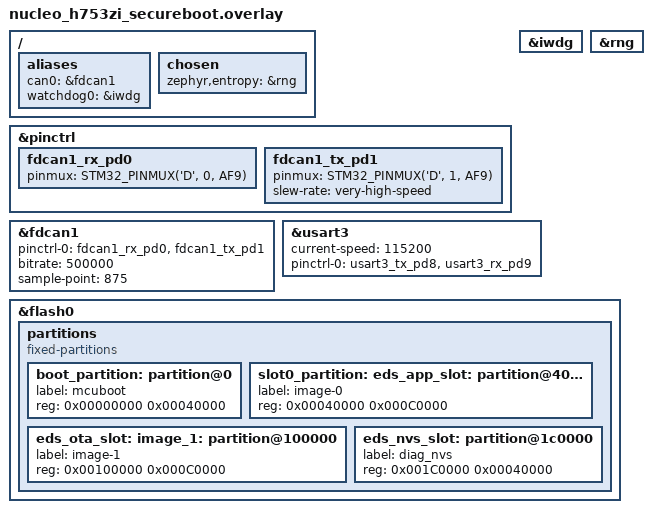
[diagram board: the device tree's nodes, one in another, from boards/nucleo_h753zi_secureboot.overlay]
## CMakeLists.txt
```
# =============================================================================
# Xaloqi Zephyr-Reference-ECU
# CMakeLists.txt (project root)
#
# PURPOSE: Wires Xaloqi EDS — pulled in as a west module (see west.yml) — plus
#          this repo's own application sources into a single Zephyr app
#          target, with optional code generation from diagnostics_config.yaml.
#
#          Phase 1 (this phase): native_sim only. The real-hardware board
#          target lands in Phase 2 — see README.md.
#
# USAGE:
#   west build -b native_sim .
#
#   # Skip codegen if generated/ files are already present (the default for
#   # a fresh clone — see "Pre-committed generated C" in README.md):
#   west build -b native_sim . -- -DDIAG_SKIP_CODEGEN=ON
#
# SPDX-License-Identifier: Apache-2.0
# =============================================================================

cmake_minimum_required(VERSION 3.20.0)

# ---------------------------------------------------------------------------
# Option: CAN FD (the Pi 5 CAN FD bench), CAN build only
#
#   nucleo_h753zi: FDCAN1 in CAN FD mode with a 2 Mbit/s data phase
#                  (boards/nucleo_h753zi_canfd.*; arbitration unchanged at 500 kbit/s)
#   xenvm:         CAN FD over virtio-can (boards/xenvm_can_fd.conf; xenvm/run.sh can
#                  with XENVM_CAN_FD=1)
# and, on both, EDS's ISO-TP built with CAN FD (ISOTP_ENABLE_CAN_FD, use_fd set
# in src/main.c). Off by default, so the default images are unchanged. Must come
# before find_package(Zephyr), which reads the extra conf and overlay.
# ---------------------------------------------------------------------------
option(DIAG_CAN_FD "CAN FD on the CAN controller and in ISO-TP (nucleo_h753zi, xenvm)" OFF)
if(DIAG_CAN_FD)
    if(DIAG_DOIP_ONLY_BUILD)
        message(FATAL_ERROR "[REF-ECU] DIAG_CAN_FD is a CAN option; it cannot combine with DIAG_DOIP_ONLY_BUILD.")
    endif()
    if(BOARD MATCHES "^nucleo_h753zi")
        list(APPEND EXTRA_CONF_FILE ${CMAKE_CURRENT_SOURCE_DIR}/boards/nucleo_h753zi_canfd.conf)
        list(APPEND EXTRA_DTC_OVERLAY_FILE ${CMAKE_CURRENT_SOURCE_DIR}/boards/nucleo_h753zi_canfd.overlay)
    elseif(BOARD MATCHES "^xenvm")
        list(APPEND EXTRA_CONF_FILE ${CMAKE_CURRENT_SOURCE_DIR}/boards/xenvm_can_fd.conf)
    else()
        message(FATAL_ERROR "[REF-ECU] DIAG_CAN_FD is defined for nucleo_h753zi and xenvm only (got '${BOARD}').")
    endif()
endif()

find_package(Zephyr REQUIRED HINTS $ENV{ZEPHYR_BASE})

project(zephyr_reference_ecu
    VERSION     0.1.0
    LANGUAGES   C
    DESCRIPTION "Xaloqi Zephyr-Reference-ECU — ReferenceBCM"
)

set(CMAKE_C_STANDARD          11)
set(CMAKE_C_STANDARD_REQUIRED ON)
set(CMAKE_C_EXTENSIONS        OFF)

# ---------------------------------------------------------------------------
# Compiler flags
#
# -Wpedantic and -Wconversion are deliberately absent — Zephyr's own headers
# trip both (C11/GCC extensions, cbprintf sign-conversion noise). Same
# exclusion EDS's own examples make, for the same reason.
# ---------------------------------------------------------------------------
target_compile_options(app PRIVATE
    -Wall
    -Wextra
    -Wshadow
    -Wdouble-promotion
    -Wundef
    -Wno-unused-parameter
    -Wno-sign-conversion
)

# ---------------------------------------------------------------------------
# Xaloqi EDS — resolved via the west module variable Zephyr's module system
# generates from EDS's zephyr/module.yml ("name: xaloqi-eds").
# ---------------------------------------------------------------------------
if(NOT DEFINED ZEPHYR_XALOQI_EDS_MODULE_DIR)
    message(FATAL_ERROR
        "\n"
        "[REF-ECU] ERROR: Xaloqi EDS west module not found.\n"
        "       Expected ZEPHYR_XALOQI_EDS_MODULE_DIR to be set by Zephyr's\n"
        "       module system (see west.yml and EDS's zephyr/module.yml).\n"
        "       Did you run 'west update'?\n"
    )
endif()

set(DIAG_ROOT "${ZEPHYR_XALOQI_EDS_MODULE_DIR}")

set(DIAG_CONFIG_YAML    "${CMAKE_CURRENT_SOURCE_DIR}/diagnostics_config.yaml")
set(DIAG_CODEGEN_SCRIPT "${DIAG_ROOT}/tools/codegen.py")
set(DIAG_GENERATED_DIR  "${CMAKE_CURRENT_SOURCE_DIR}/generated")

# Sentinel: file whose timestamp CMake uses to detect when codegen must re-run.
set(CODEGEN_SENTINEL "${DIAG_GENERATED_DIR}/safety_config.h")

# ---------------------------------------------------------------------------
# Option: disable automatic code generation
#
# Default OFF matches EDS's own examples. A fresh clone of THIS repo should
# flip it ON implicitly via the configure-time check below: codegen needs
# the commercial tools/templates/ this repo does not ship (see
# COMMERCIAL_NOTICE.md) — rather than fail with a confusing Jinja2 error,
# detect the missing templates and fall back to the pre-committed generated/
# tree with a clear message.
# ---------------------------------------------------------------------------
option(DIAG_SKIP_CODEGEN
    "Skip auto-running EDS's tools/codegen.py (use pre-existing generated/ files)"
    OFF
)

# ---------------------------------------------------------------------------
# Option: build the DoIP-only variant (Phase 4) instead of CAN
#
# Selects src/main_doip.c instead of src/main.c, and DoIP transport sources
# instead of ISO-TP/CAN — never both in the same image. See src/main_doip.c's
# own header comment for why this repo does not attempt to run CAN and DoIP
# concurrently (EDS ships no proven architecture for it).
# ---------------------------------------------------------------------------
option(DIAG_DOIP_ONLY_BUILD
    "Build the DoIP transport variant (src/main_doip.c) instead of CAN (src/main.c)"
    OFF
)

# ---------------------------------------------------------------------------
# Option: secure boot (Phase 4) — MCUboot image-policy gate, CAN or DoIP
#
# Adds EDS's flash-ops + MCUboot image-policy sources and the boot-confirm /
# image-policy-registration calls in src/main.c or src/main_doip.c (guarded
# by the DIAG_SECURE_BOOT_BUILD compile definition this sets). Combines with
# DIAG_DOIP_ONLY_BUILD for firmware download over DoIP [EDS#425]. Requires building
# and flashing MCUboot itself separately, and the MCUboot-aware partition
# table in boards/nucleo_h753zi_secureboot.overlay — see README.md "Phase 4".
#
# Scoped to exactly what EDS ships today: MCUboot swap, image-policy gate,
# fail-closed production guard. Firmware authenticity / anti-rollback
# (EDS#319) is open upstream and explicitly excluded.
# ---------------------------------------------------------------------------
option(DIAG_SECURE_BOOT_BUILD
    "Add MCUboot image-policy support (requires MCUboot built and flashed separately)"
    OFF
)

# ---------------------------------------------------------------------------
# Option: bench-only slow RoutineControl (RID 0xF0F0), as in EDS's basic_ecu
#
# A 0x31 routine that answers NRC 0x78 and busy-waits in bounded steps, so the
# response-pending cadence (0x78 keepalives, P2/P2*) can be measured on this
# ECU without flash wear [EDS#282]. Default OFF: a normal image has no 0xF0F0.
# NOT FOR PRODUCTION. Needs an EDS that has the generic response-pending path
# (EDS#555/#559, after v1.26.1); the configure step says so if the pinned EDS
# does not.
# ---------------------------------------------------------------------------
option(DIAG_BENCH_SLOW_ROUTINE
    "Bench only: slow 0x31 routine (RID 0xF0F0) for the response-pending path"
    OFF
)

# DIAG_CAN_FD (declared before find_package above): every EDS source is compiled
# into this app target, so all of them see the same ISOTP_ENABLE_CAN_FD, which
# changes isotp_ctx_t's layout.
if(DIAG_CAN_FD)
    target_compile_definitions(app PRIVATE ISOTP_ENABLE_CAN_FD=1 DIAG_CAN_FD=1)
endif()

# ---------------------------------------------------------------------------
# DIAG_CAN_ECU_INDEX — ISO 15765-4 physical address pair of this ECU (CAN build).
# Unset (the default): the generated response ID (0x7E8) and physical request ID
# 0x7E0, so every existing image is unchanged. 0..7: request 0x7E0+n, response
# 0x7E8+n, so two of these ECUs can share one bus (the Pi 5 bench runs the
# NUCLEO as ECU 0 and the xenvm DomZ as ECU 1). The functional ID 0x7DF stays
# shared, as ISO 15765-4 intends: each ECU answers it on its own response ID.
# ---------------------------------------------------------------------------
set(DIAG_CAN_ECU_INDEX "" CACHE STRING "ISO 15765-4 ECU index 0..7 (empty: generated IDs)")
if(NOT DIAG_CAN_ECU_INDEX STREQUAL "")
    if(NOT DIAG_CAN_ECU_INDEX MATCHES "^[0-7]$")
        message(FATAL_ERROR "DIAG_CAN_ECU_INDEX must be 0..7, got '${DIAG_CAN_ECU_INDEX}'")
    endif()
    target_compile_definitions(app PRIVATE DIAG_CAN_ECU_INDEX=${DIAG_CAN_ECU_INDEX}U)
endif()

if(NOT DIAG_SKIP_CODEGEN AND NOT EXISTS "${DIAG_ROOT}/tools/templates")
    message(STATUS
        "[REF-ECU] Commercial tools/templates/ not present (expected — this "
        "is the free tier). Using the pre-committed generated/ tree instead. "
        "See README.md 'Tiers'.")
    set(DIAG_SKIP_CODEGEN ON)
endif()

if(NOT DIAG_SKIP_CODEGEN)

    find_package(Python3 COMPONENTS Interpreter QUIET)

    if(NOT Python3_FOUND)
        message(FATAL_ERROR
            "\n"
            "[REF-ECU] ERROR: Python3 interpreter not found.\n"
            "       Cannot run EDS's tools/codegen.py.\n"
            "       Install Python3 (>= 3.9) with: pip install pyyaml jinja2\n"
            "       Or build with -DDIAG_SKIP_CODEGEN=ON to use the\n"
            "       pre-committed generated/ tree instead.\n"
        )
    endif()

    file(GLOB DIAG_TEMPLATES "${DIAG_ROOT}/tools/templates/*.j2")

    add_custom_command(
        OUTPUT   "${CODEGEN_SENTINEL}"
        COMMAND  "${Python3_EXECUTABLE}"
                 "${DIAG_CODEGEN_SCRIPT}"
                 --config "${DIAG_CONFIG_YAML}"
                 --out    "${DIAG_GENERATED_DIR}"
                 --safety-wrappers
                 --asil-level B
                 --no-manifest
        DEPENDS
            "${DIAG_CONFIG_YAML}"
            "${DIAG_CODEGEN_SCRIPT}"
            ${DIAG_TEMPLATES}
        COMMENT  "[REF-ECU] Generating sources from diagnostics_config.yaml (ASIL-B)..."
        VERBATIM
    )

    add_custom_target(run_codegen
        DEPENDS "${CODEGEN_SENTINEL}"
        COMMENT "[REF-ECU] run_codegen complete."
    )

else()

    message(STATUS
        "[REF-ECU] DIAG_SKIP_CODEGEN=ON — using existing files in ${DIAG_GENERATED_DIR}")

endif()

# ---------------------------------------------------------------------------
# Configure-time check: the one hand-edited "generated/ delta" this repo
# makes (generated/routine_handlers.c's four [APP HOOK] bodies — see that
# file's own banner and src/bcm_state.h) must survive a regeneration.
# ---------------------------------------------------------------------------
if(EXISTS "${DIAG_GENERATED_DIR}/routine_handlers.c")
    file(READ "${DIAG_GENERATED_DIR}/routine_handlers.c" _ROUTINE_HANDLERS_SRC)
    string(FIND "${_ROUTINE_HANDLERS_SRC}" "[APP HOOK]" _APP_HOOK_POS)
    if(_APP_HOOK_POS EQUAL -1)
        message(FATAL_ERROR
            "\n"
            "[REF-ECU] ERROR: generated/routine_handlers.c no longer contains "
            "the [APP HOOK] markers.\n"
            "       If you regenerated this file from diagnostics_config.yaml, "
            "reapply the four bodies documented in src/bcm_state.h, or this "
            "ECU's RoutineControl actuations silently do nothing.\n"
        )
    endif()
endif()

# ---------------------------------------------------------------------------
# Include directories
# ---------------------------------------------------------------------------
target_include_directories(app PRIVATE
    ${DIAG_ROOT}/core
    ${DIAG_ROOT}/core/uds_services
    ${DIAG_ROOT}/transport
    ${DIAG_ROOT}/config
    ${DIAG_ROOT}/platform
    ${DIAG_ROOT}/platform/zephyr
    ${DIAG_GENERATED_DIR}
    ${CMAKE_CURRENT_SOURCE_DIR}/src
)
if(DIAG_DOIP_ONLY_BUILD)
    target_include_directories(app PRIVATE ${DIAG_ROOT}/transport/doip)
endif()

# ---------------------------------------------------------------------------
# Source files
# ---------------------------------------------------------------------------
include(${DIAG_ROOT}/cmake/eds_service_sources.cmake)

target_sources(app PRIVATE

    # ── This repo's own application layer (Apache-2.0) ────────────────────
    ${CMAKE_CURRENT_SOURCE_DIR}/src/bcm_state.c
    ${CMAKE_CURRENT_SOURCE_DIR}/src/bcm_storage.c
    ${CMAKE_CURRENT_SOURCE_DIR}/src/bcm_debounce.c

    # ── EDS UDS core ────────────────────────────────────────────────────
    ${DIAG_ROOT}/core/uds_server.c
    ${DIAG_ROOT}/core/uds_session.c
    ${DIAG_ROOT}/core/uds_security.c
    ${DIAG_ROOT}/core/uds_safety.c
    ${DIAG_ROOT}/core/uds_security_algo.c
    ${DIAG_ROOT}/core/uds_aes_cmac.c
    ${DIAG_ROOT}/core/uds_access_table.c
    ${DIAG_ROOT}/core/uds_comm_control.c
    ${DIAG_ROOT}/core/uds_session_stats.c
    ${DIAG_ROOT}/core/uds_security_nvm.c
    ${EDS_SERVICE_SRCS}
    ${DIAG_ROOT}/core/uds_transfer_ctx.c
    ${DIAG_ROOT}/platform/uds_flash_ops.c
    ${DIAG_ROOT}/platform/uds_image_policy.c

    # ── EDS configuration databases ─────────────────────────────────────
    ${DIAG_ROOT}/config/did_database.c
    ${DIAG_ROOT}/config/dtc_database.c
    ${DIAG_ROOT}/config/routine_database.c
    ${DIAG_ROOT}/config/dtc_mirror.c

    # ── EDS Zephyr platform abstraction (transport-independent) ──────────
    ${DIAG_ROOT}/platform/zephyr/zephyr_mutex.c
    ${DIAG_ROOT}/platform/zephyr/zephyr_platform_api.c
    # Both entry points arm and feed the watchdog (diag_wdt_init/feed);
    # on native_sim (CONFIG_WATCHDOG=n) it compiles to its degraded no-op.
    ${DIAG_ROOT}/platform/zephyr/zephyr_wdt.c

    # ── Generated sources ────────────────────────────────────────────────
    ${DIAG_GENERATED_DIR}/did_handlers.c
    ${DIAG_GENERATED_DIR}/uds_init.c
    ${DIAG_GENERATED_DIR}/did_safety_wrappers.c
    ${DIAG_GENERATED_DIR}/routine_handlers.c
)

# ---------------------------------------------------------------------------
# Transport-specific entry point and sources — CAN (default) or DoIP
# (DIAG_DOIP_ONLY_BUILD), never both. See src/main_doip.c's header comment
# for why this repo does not attempt both transports in one image.
# ---------------------------------------------------------------------------
if(DIAG_DOIP_ONLY_BUILD)
    target_sources(app PRIVATE
        ${CMAKE_CURRENT_SOURCE_DIR}/src/main_doip.c
        ${DIAG_ROOT}/transport/doip/doip_server.c
        ${DIAG_ROOT}/transport/doip/zephyr_lwip.c
        ${DIAG_ROOT}/platform/zephyr/platform_doip.c
    )
    target_compile_definitions(app PRIVATE EDS_DOIP_ONLY_BUILD=1)
else()
    target_sources(app PRIVATE
        ${CMAKE_CURRENT_SOURCE_DIR}/src/main.c
        ${DIAG_ROOT}/transport/isotp.c
        ${DIAG_ROOT}/transport/can_transport.c
        ${DIAG_ROOT}/platform/zephyr/zephyr_can.c
        ${DIAG_ROOT}/platform/zephyr/zephyr_port.c
        ${DIAG_ROOT}/platform/zephyr/zephyr_timer.c
    )
endif()

# ---------------------------------------------------------------------------
# Secure boot — either transport [EDS#425]. Same sources and definition for
# CAN and DoIP; placed after the transport sources so the CAN build's link
# order is unchanged.
# ---------------------------------------------------------------------------
if(DIAG_SECURE_BOOT_BUILD)
    target_sources(app PRIVATE
        # Registered with zephyr_flash_ops_init() by both entry points
        # (src/main.c since #19, src/main_doip.c).
        ${DIAG_ROOT}/platform/zephyr/zephyr_flash_ops.c
        # Called from both entry points (zephyr_mcuboot_image_policy_init())
        ${DIAG_ROOT}/platform/zephyr/zephyr_mcuboot_image_policy.c
        # Streaming SHA-256 + MCUboot header/TLV parser — used by the
        # image-policy digest check above
        ${DIAG_ROOT}/platform/uds_sha256.c
        ${DIAG_ROOT}/platform/uds_mcuboot_image.c
    )
    target_compile_definitions(app PRIVATE DIAG_SECURE_BOOT_BUILD=1)
endif()

# ---------------------------------------------------------------------------
# Bench-only slow routine (DIAG_BENCH_SLOW_ROUTINE), both transports.
# ---------------------------------------------------------------------------
if(DIAG_BENCH_SLOW_ROUTINE)
    if(NOT EXISTS "${DIAG_ROOT}/platform/zephyr/bench_slow_routine.c")
        message(FATAL_ERROR
            "\n"
            "[REF-ECU] ERROR: DIAG_BENCH_SLOW_ROUTINE=ON, but the EDS in "
            "${DIAG_ROOT} has no platform/zephyr/bench_slow_routine.c.\n"
            "       The bench routine ships with EDS#559, after v1.26.1. Point "
            "west.yml's EDS revision at a commit that has it (a local, "
            "uncommitted change is fine for a bench).\n"
        )
    endif()
    target_sources(app PRIVATE ${DIAG_ROOT}/platform/zephyr/bench_slow_routine.c)
    target_compile_definitions(app PRIVATE DIAG_BENCH_SLOW_ROUTINE=1)
endif()

# ---------------------------------------------------------------------------
# NVM store: platform-conditional source selection (same pattern as EDS's
# own examples/safeboot_ecu/CMakeLists.txt, the reference for this exact
# board).
#
#   native_sim      — nvm_store_mock.c, RAM-backed, no real flash to resolve.
#   nucleo_h753zi   — nvm_store_append.c, the append-only backend EDS#304
#                     introduced for STM32H7 boards: their uniform 128 KB
#                     erase sectors exceed nvs_fs.sector_size's uint16_t
#                     range, so nvm_store.c's classic NVS backend cannot
#                     mount this partition at all on this part.
#
# Exactly one must be compiled per build; any two would produce duplicate-
# symbol linker errors (all three define the same nvm_store_* API).
# ---------------------------------------------------------------------------
if(CONFIG_BOARD_NATIVE_SIM)
    target_sources(app PRIVATE ${DIAG_ROOT}/platform/zephyr/nvm_store_mock.c)
elseif(CONFIG_BOARD_NUCLEO_H753ZI)
    target_sources(app PRIVATE ${DIAG_ROOT}/platform/zephyr/nvm_store_append.c)
    target_compile_definitions(app PRIVATE DIAG_NVM_BACKEND_APPEND=1)
else()
    target_sources(app PRIVATE ${DIAG_ROOT}/platform/zephyr/nvm_store.c)
endif()

if(NOT DIAG_SKIP_CODEGEN AND TARGET run_codegen)
    add_dependencies(app run_codegen)
endif()

# Required for the build to compile: _Static_assert in uds_types.h fires at
# translation-unit level whenever sizeof(uds_msg_buf_t) > EDS_MSG_BUF_MAX_STACK_BYTES.
target_compile_definitions(app PRIVATE EDS_MSG_BUF_MAX_STACK_BYTES=8192)
```

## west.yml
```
manifest:
  version: "0.13"

  remotes:
    - name: zephyrproject-rtos
      url-base: https://github.com/zephyrproject-rtos
    - name: xaloqi
      url-base: https://github.com/Xaloqi

  projects:
    - name: zephyr
      remote: zephyrproject-rtos
      revision: v3.7.0
      path: zephyr
      import:
        file: west.yml

    - name: EDS
      remote: xaloqi
      revision: v1.29.0
      path: modules/xaloqi-eds

  self:
    path: Zephyr-Reference-ECU
```

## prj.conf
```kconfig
# =============================================================================
# Xaloqi Zephyr-Reference-ECU
# prj.conf
#
# Base project configuration. native_sim-specific overrides live in
# boards/native_sim.conf (Phase 1 ships no other board target).
# =============================================================================

# --- CAN driver ---
CONFIG_CAN=y
CONFIG_CAN_INIT_PRIORITY=80
CONFIG_STATS=y
CONFIG_CAN_STATS=y

# --- Kernel / threading ---
CONFIG_MULTITHREADING=y
CONFIG_THREAD_STACK_INFO=y
CONFIG_THREAD_NAME=y
CONFIG_THREAD_MONITOR=y

# --- Tick rate: 1 ms required for ISO-TP timer accuracy ---
CONFIG_SYS_CLOCK_TICKS_PER_SEC=1000
CONFIG_TICKLESS_KERNEL=n

# --- Watchdog ---
CONFIG_WATCHDOG=y
CONFIG_WDT_DISABLE_AT_BOOT=n
CONFIG_DIAG_WDT_WINDOW_MS=100

# --- Logging ---
CONFIG_LOG=y
CONFIG_LOG_DEFAULT_LEVEL=3
CONFIG_LOG_BACKEND_UART=y
CONFIG_LOG_BUFFER_SIZE=2048

# --- Safety hardening ---
CONFIG_ASSERT=y
CONFIG_STACK_CANARIES=y
CONFIG_STACK_SENTINEL=y

# --- C library ---
CONFIG_NEWLIB_LIBC=y

# --- No heap (MISRA-21.3) ---
CONFIG_HEAP_MEM_POOL_SIZE=0

# --- UDS stack parameters ---
# S3 and the SecurityAccess lockout come from diagnostics_config.yaml (timing:
# / safety:), not Kconfig. ISO-TP timeouts use EDS's ISO 15765-2:2024 defaults
# (1000 ms). The pins that used to be here were ignored by EDS until
# Xaloqi/EDS#453 and would now force the old 25-150 ms values (Xaloqi/EDS#455).

# --- Diagnostics task ---
CONFIG_DIAG_TASK_STACK_SIZE=4096
CONFIG_DIAG_TASK_PRIORITY=5

# --- Build output ---
CONFIG_BUILD_OUTPUT_BIN=y
CONFIG_BUILD_OUTPUT_HEX=y
```

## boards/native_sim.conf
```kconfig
# =============================================================================
# Xaloqi Zephyr-Reference-ECU
# boards/native_sim.conf
#
# native_sim-specific Kconfig overrides, auto-merged by Zephyr CMake on top
# of prj.conf for this board only (Zephyr convention: <app>/boards/<BOARD>.conf
# is picked up automatically). See Xaloqi EDS's own
# boards/native_sim/native_sim.conf for the full rationale behind each
# override below — Zephyr 3.7 promotes several Kconfig dependency warnings
# to fatal errors on native_sim.
# =============================================================================

CONFIG_CAN_LOOPBACK=y
CONFIG_POSIX_API=y
CONFIG_STACK_CANARIES=n
CONFIG_CAN_STATS=n
CONFIG_LOG_MODE_DEFERRED=y
CONFIG_LOG_BACKEND_UART=n
CONFIG_LOG_BACKEND_NATIVE_POSIX=y
CONFIG_NEWLIB_LIBC=y
CONFIG_REBOOT=y
CONFIG_LOG_DEFAULT_LEVEL=2
CONFIG_WATCHDOG=n
```

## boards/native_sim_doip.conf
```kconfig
# =============================================================================
# Xaloqi Zephyr-Reference-ECU
# boards/native_sim_doip.conf
#
# native_sim loopback-only config for the DoIP build, adapted from Xaloqi
# EDS's own examples/basic_ecu_doip/boards/native_sim/native_sim_doip.conf.
#
# Reachable only from inside the native_sim process itself, not from the
# host OS by any method (CONFIG_NET_LOOPBACK blocks NET_L2_ETHERNET's
# default — a known, disclosed Zephyr/native_sim limitation, EDS#257, not
# something this repo can fix). This file exists for a quick local sanity
# build only, needing no host network setup. For real DoIP bring-up, use
# boards/nucleo_h753zi_doip.conf on real hardware — see README.md "Phase 4".
#
# BUILDING:
#   west build -b native_sim . -- \
#       -DDIAG_SKIP_CODEGEN=ON \
#       -DDIAG_DOIP_ONLY_BUILD=ON \
#       -DEXTRA_CONF_FILE=boards/native_sim_doip.conf
# =============================================================================

CONFIG_POSIX_API=y
CONFIG_NET_LOOPBACK=y
CONFIG_NET_NATIVE=y

# --- Networking base (prj.conf has none — the CAN build needs none) -------
# NET_SOCKETS_POSIX_NAMES intentionally omitted: conflicts with POSIX_API=y.
CONFIG_NETWORKING=y
CONFIG_NET_IPV4=y
CONFIG_NET_TCP=y
CONFIG_NET_SOCKETS=y
CONFIG_NET_IF_MAX_IPV4_COUNT=1
CONFIG_NET_MAX_CONN=8
CONFIG_NET_TCP_MAX_SEND_WINDOW_SIZE=4096
CONFIG_POSIX_MAX_FDS=16

CONFIG_LOG_MODE_DEFERRED=y
CONFIG_LOG_BACKEND_UART=n
CONFIG_LOG_BACKEND_NATIVE_POSIX=y

CONFIG_STACK_CANARIES=n
CONFIG_NEWLIB_LIBC=y

CONFIG_NET_DRIVERS=y
CONFIG_ETH_NATIVE_POSIX=y

CONFIG_LOG_DEFAULT_LEVEL=2
CONFIG_WATCHDOG=n
```

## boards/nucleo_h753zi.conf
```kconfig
# =============================================================================
# Xaloqi Zephyr-Reference-ECU
# boards/nucleo_h753zi.conf
#
# Board-specific Kconfig overrides for the NUCLEO-H753ZI, merged on top of
# prj.conf. Copied from Xaloqi EDS's own confirmed boards/nucleo_h753zi/
# nucleo_h753zi.conf (Zephyr 3.7 / STM32H7 Cortex-M7 specifics — hidden
# Kconfig symbols, MPU vs stack-sentinel conflict, DT-gated CAN/IWDG
# driver selection) — see that file for the full per-symbol rationale.
# =============================================================================

# --- UART3 for ST-LINK virtual COM port logging ------------------------------
CONFIG_SERIAL=y
CONFIG_UART_STM32=y
CONFIG_LOG_BACKEND_UART=y
CONFIG_LOG_MODE_DEFERRED=y
CONFIG_LOG_BUFFER_SIZE=4096

# --- Hardware watchdog (IWDG, DT-gated — do not set CONFIG_WDT_STM32_IWDG) ---
CONFIG_WATCHDOG=y
# Deliberate, not a default: Zephyr's IWDG driver arms the watchdog before
# main() (CONFIG_IWDG_STM32_INITIAL_TIMEOUT, 100 ms), so supervision starts at
# driver init rather than when main() gets round to it -- the earliest any
# option here offers. The cost is a hard budget: everything before
# src/main.c's diag_wdt_init() must finish inside those 100 ms. Measured on
# the bench (CAN build): main() reached at <1 ms uptime -- ~99 ms of margin.
# src/main.c warns at boot if that drops below half the window.
# The DoIP variant cannot meet this budget (its pre-main waits for the network)
# and overrides it -- see boards/nucleo_h753zi_doip.conf.
CONFIG_WDT_DISABLE_AT_BOOT=n

# --- ARM MPU (Cortex-M7, 16-region) ------------------------------------------
CONFIG_ARM_MPU=y
CONFIG_MPU_ALLOW_FLASH_WRITE=y

# --- MPU_STACK_GUARD (auto-selected by ARM_MPU) conflicts with the sentinel --
CONFIG_STACK_SENTINEL=n

# --- Stack canaries: prj.conf's STACK_CANARIES=y stands on this board ---------
# The kernel seeds __stack_chk_guard after PRE_KERNEL_2 through
# entropy_get_entropy_isr() on zephyr,entropy. The STM32 RNG driver initialises
# at PRE_KERNEL_1 and implements that call, so the canary comes from the
# hardware RNG. Canaries do not conflict with the MPU stack guard: the guard
# catches running off the end of a stack, the canary an overrun inside a frame.
# Ask EDS to fail the build if they are ever dropped or not RNG-seeded.
CONFIG_EDS_REQUIRE_STACK_CANARIES=y

# --- Hardware RNG — required for the AES-CMAC SecurityAccess challenge ------
CONFIG_ENTROPY_GENERATOR=y

# --- Flash + NVS (required by platform/nvm_store.c) --------------------------
CONFIG_FLASH=y
CONFIG_FLASH_MAP=y
CONFIG_NVS=y
```

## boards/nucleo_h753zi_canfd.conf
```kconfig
# =============================================================================
# Xaloqi Zephyr-Reference-ECU
# boards/nucleo_h753zi_canfd.conf
#
# Added by -DDIAG_CAN_FD=ON (CMakeLists.txt), on top of nucleo_h753zi.conf:
# FDCAN1 in CAN FD mode for the Pi 5 CAN FD bench. The data-phase timing is in
# boards/nucleo_h753zi_canfd.overlay.
# =============================================================================
CONFIG_CAN_FD_MODE=y
```

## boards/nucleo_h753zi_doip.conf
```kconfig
# =============================================================================
# Xaloqi Zephyr-Reference-ECU
# boards/nucleo_h753zi_doip.conf
#
# Real-hardware DoIP config for the NUCLEO-H753ZI, adapted from Xaloqi EDS's
# own confirmed examples/basic_ecu_doip/boards/nucleo_h753zi/
# nucleo_h753zi_doip.conf — not re-derived.
#
# NUCLEO-H753ZI's Zephyr board support already wires the STM32 Ethernet MAC
# and PHY in devicetree with status "okay" (RMII pinctrl, MDIO) — no board
# overlay needed, only this application-level net stack config.
#
# HOST-SIDE SETUP THIS CONF EXPECTS: a direct Ethernet cable from this board
# to the host machine's own NIC, with the host given a static IP on the same
# /24, e.g.:
#   sudo ip addr add 10.10.10.2/24 dev <host-iface>
# No router, no DHCP server — a direct point-to-point bench link.
#
# JUMPERS: JP6 and JP7 must be ON for Ethernet — see README.md "Phase 4"
# and the bill of materials (PA2/PB13 otherwise conflict with the ST
# Zio/morpho connectors, per Zephyr's own board DTS warning).
#
# BUILDING:
#   west build -b nucleo_h753zi . -- \
#       -DDIAG_SKIP_CODEGEN=ON \
#       -DDIAG_DOIP_ONLY_BUILD=ON \
#       -DEXTRA_CONF_FILE=boards/nucleo_h753zi_doip.conf
# =============================================================================

# --- Networking base (prj.conf has none — the CAN build needs none) -------
CONFIG_NETWORKING=y
CONFIG_NET_IPV4=y
CONFIG_NET_TCP=y
CONFIG_NET_SOCKETS=y
CONFIG_NET_IF_MAX_IPV4_COUNT=1
CONFIG_NET_MAX_CONN=8
CONFIG_NET_TCP_MAX_SEND_WINDOW_SIZE=4096
CONFIG_POSIX_MAX_FDS=16

# --- Real Ethernet driver (auto-selected once NET_L2_ETHERNET is on) -------
CONFIG_NET_L2_ETHERNET=y

# --- Static IPv4 — point-to-point bench link, no DHCP server present -------
CONFIG_NET_CONFIG_SETTINGS=y
CONFIG_NET_CONFIG_NEED_IPV4=y
CONFIG_NET_CONFIG_MY_IPV4_ADDR="10.10.10.1"
CONFIG_NET_CONFIG_MY_IPV4_GW="10.10.10.2"
CONFIG_NET_CONFIG_MY_IPV4_NETMASK="255.255.255.0"

# --- Real hardware: keep console/log on the ST-LINK VCP (board default via
#     zephyr,console = &usart3) ---
CONFIG_LOG=y
CONFIG_LOG_DEFAULT_LEVEL=3

# --- Watchdog: armed by src/main_doip.c, NOT by Zephyr at boot ------------
# Without this line Zephyr's IWDG driver arms the watchdog in
# iwdg_stm32_init(), before main(), with CONFIG_IWDG_STM32_INITIAL_TIMEOUT
# (100 ms). That cannot work on this variant: net_config_init() also runs
# before main() and blocks until the interface is up, bounded only by
# CONFIG_NET_CONFIG_INIT_TIMEOUT (30 s). Measured on the bench, main() starts
# 1.5-4.1 s after boot, depending on the link partner (with the host side
# configured it waits for PHY link-up, ~0.3 s after it), so a boot-armed
# IWDG resets the board every ~100 ms forever (issue #7: RCC_RSR
# 0x04460000 = IWDG1RSTF|PINRSTF|CPURSTF).
#
# So boot-time arming is off, and src/main_doip.c arms the IWDG explicitly
# with diag_wdt_init() at the top of main() and feeds it from the UDS tick
# task. Consequences, stated so nobody infers more:
#   - boot up to main() (1.5-4.1 s measured, up to 30 s) is unsupervised;
#   - from main() on, the UDS tick path and the DoIP server loop are
#     supervised (the loop via EDS#399's check-in); a dead Ethernet link is
#     not -- see "WATCHDOG SUPERVISION" in src/main_doip.c.
# The CAN build deliberately keeps boot-time arming (boards/nucleo_h753zi.conf);
# its pre-main has no network wait. Do not copy this line there.
CONFIG_WDT_DISABLE_AT_BOOT=y
```

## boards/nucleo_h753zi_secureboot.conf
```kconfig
# =============================================================================
# Xaloqi Zephyr-Reference-ECU
# boards/nucleo_h753zi_secureboot.conf
#
# Additive on top of the auto-picked-up boards/nucleo_h753zi.conf (Zephyr
# merges both — this file only needs the MCUboot-specific delta). Adapted
# from Xaloqi EDS's own confirmed examples/safeboot_ecu/boards/nucleo_h753zi/
# nucleo_h753zi.conf.
#
# Full dependency chain (confirmed against the actual subsys/dfu/Kconfig
# source, v3.7.0):
#   menuconfig IMG_MANAGER          depends on STREAM_FLASH
#     choice "Image manager"        default MCUBOOT_IMG_MANAGER
#       MCUBOOT_IMG_MANAGER         depends on FLASH_MAP (already set)
#                                   select MCUBOOT_BOOTUTIL_LIB (provides
#                                   boot_is_img_confirmed()/
#                                   boot_write_img_confirmed())
# CONFIG_STREAM_FLASH is the actual load-bearing one: without it the whole
# IMG_MANAGER menu is invisible, so nothing inside it takes effect no
# matter what else is set here.
# =============================================================================

CONFIG_STREAM_FLASH=y
CONFIG_IMG_MANAGER=y
CONFIG_BOOTLOADER_MCUBOOT=y
CONFIG_MCUBOOT_IMG_MANAGER=y

# --- MCUboot secondary slot write support -----------------------------------
# flash_area_write() requires this to allow writes to non-erase-aligned
# offsets. STM32H753 flash requires 256-bit (32-byte) aligned writes.
CONFIG_FLASH_PAGE_LAYOUT=y
```

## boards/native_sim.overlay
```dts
/ {
	aliases {
		can0 = &can_loopback0;
	};
};

&can_loopback0 {
	status = "okay";
};
```

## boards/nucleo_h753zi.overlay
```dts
/*
 * =============================================================================
 * Xaloqi Zephyr-Reference-ECU
 * boards/nucleo_h753zi.overlay
 *
 * Device Tree overlay for the NUCLEO-H753ZI board — Phase 2 hardware target.
 * FDCAN1 pinmux, bitrate and sample point are reused verbatim from Xaloqi
 * EDS's own confirmed reference (boards/nucleo_h753zi/nucleo_h753zi.overlay
 * in the Xaloqi/EDS repo) — not re-derived here.
 *
 * HARDWARE SETUP (see README.md "Bill of materials"):
 *   NUCLEO-H753ZI → Waveshare SN65HVD230 (3.3V CAN transceiver)
 *   PD0 (FDCAN1_RX) → transceiver RXD
 *   PD1 (FDCAN1_TX) → transceiver TXD
 *   3.3V / GND      → transceiver VCC / GND
 *   CANH / CANL     → the bus
 *
 * NOT MCUboot. This reference ships no secure-boot or DFU capability in
 * this phase (EDS#319 is open upstream, excluded per the proposal's ⬥7) —
 * the firmware runs directly from flash offset 0, no bootloader slots.
 * The flash partition table below exists only to reserve NVS space for
 * EDS's own DTC-mirror persistence; it carries none of EDS's own
 * boards/nucleo_h753zi/nucleo_h753zi.overlay MCUboot image-0/image-1
 * complexity because that complexity exists for DFU, which this repo
 * does not implement.
 * =============================================================================
 */

#include <zephyr/dt-bindings/pinctrl/stm32-pinctrl.h>

/* ── FDCAN1 pin control — PD0/PD1, verbatim from EDS's own reference ──────── */
&pinctrl {
	fdcan1_rx_pd0: fdcan1_rx_pd0 {
		pinmux = <STM32_PINMUX('D', 0, AF9)>;
	};
	fdcan1_tx_pd1: fdcan1_tx_pd1 {
		pinmux = <STM32_PINMUX('D', 1, AF9)>;
		slew-rate = "very-high-speed";
	};
};

/* ── FDCAN1 node — classic CAN 2.0B at 500 kbit/s, 87.5% sample point ─────── */
&fdcan1 {
	status = "okay";
	pinctrl-0 = <&fdcan1_rx_pd0 &fdcan1_tx_pd1>;
	pinctrl-names = "default";
	bitrate      = <500000>;
	sample-point = <875>;
};

/* ── Alias: can0 → fdcan1 (src/main.c uses DT_ALIAS(can0)) ────────────────── */
/ {
	aliases {
		can0 = &fdcan1;
		watchdog0 = &iwdg;
	};
};

/* ── Independent Watchdog ──────────────────────────────────────────────────── */
&iwdg {
	status = "okay";
};

/* ── Hardware RNG — seeds the UDS SecurityAccess AES-CMAC challenge through
 * the TRNG callback in src/diag_entropy.h (needs the zephyr,entropy chosen
 * node below and CONFIG_ENTROPY_GENERATOR=y; the build fails without them) ─ */
&rng {
	status = "okay";
};

/ {
	chosen {
		zephyr,entropy = &rng;
	};
};

/* ── UART3 for logging (ST-LINK virtual COM port) ─────────────────────────── */
&usart3 {
	status = "okay";
	current-speed = <115200>;
	pinctrl-0 = <&usart3_tx_pd8 &usart3_rx_pd9>;
	pinctrl-names = "default";
};

/* ── Flash partition table — app image + a dedicated NVS partition ─────────
 *
 * STM32H753ZI: 2 MB flash, base 0x08000000, 128 KB sectors (dual-bank).
 * No MCUboot slots — this firmware is the only thing in flash.
 *
 *   Offset     Size     Label      Purpose
 *   ─────────  ───────  ─────────  ──────────────────────────────────
 *   0x000000   1.75 MB  app        This firmware (zephyr,code-partition)
 *   0x1C0000   256 KB   diag_nvs   EDS's NVS store (2x128KB, WL minimum)
 * ─────────────────────────────────────────────────────────────────────── */
&flash0 {
	/delete-node/ partitions;

	partitions {
		compatible = "fixed-partitions";
		#address-cells = <1>;
		#size-cells = <1>;

		storage_partition: partition@0 {
			label = "app";
			reg = <0x00000000 0x001C0000>;
		};

		eds_nvs_slot: partition@1c0000 {
			label = "diag_nvs";
			reg = <0x001C0000 0x00040000>;
		};
	};
};

/ {
	chosen {
		zephyr,code-partition = &storage_partition;
	};
};
```

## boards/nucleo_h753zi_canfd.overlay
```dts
/*
 * =============================================================================
 * Xaloqi Zephyr-Reference-ECU
 * boards/nucleo_h753zi_canfd.overlay
 *
 * Added by -DDIAG_CAN_FD=ON (CMakeLists.txt), after nucleo_h753zi.overlay:
 * the CAN FD data phase of FDCAN1 for the Pi 5 CAN FD bench. The arbitration
 * phase stays 500 kbit/s at 87.5 %, so the bus, the IDs and the classic-CAN
 * tester settings are unchanged.
 *
 * Data phase: 2 Mbit/s at 80 %.
 *  - FDCAN1's kernel clock is PLL2Q = 8 MHz HSE / 4 * 120 / 3 = 80 MHz
 *    (nucleo_h753zi board DT, FDCAN_SEL), so 2 Mbit/s is 40 tq with prescaler
 *    1, and 80 % is exact. Zephyr's m_can driver turns on transmitter delay
 *    compensation by itself at that prescaler.
 *  - The Waveshare 2-CH CAN FD HAT (MCP2518FD, 40 MHz) gets 20 tq at 2 Mbit/s,
 *    80 % exact too: DomD's `ip link set canX ... dbitrate 2000000
 *    dsample-point 0.8 fd on`.
 *  - 2 Mbit/s, not more: the transceiver on this end has to be FD-rated (the
 *    SN65HVD230 is specified to 1 Mbit/s), and a bench of jumper wire and screw
 *    terminals is not a characterised harness. 5 Mbit/s (16 tq here, 8 tq on
 *    the MCP2518FD) is the next step once 2 Mbit/s runs clean.
 *
 * This ECU does not set BRS on what it sends (tp->brs stays false, src/main.c;
 * EDS v1.27.0 can, via can.fd_brs), so this data phase is used for frames the
 * ECU receives; its own FD frames go at 500 kbit/s.
 * =============================================================================
 */

&fdcan1 {
	bitrate-data      = <2000000>;
	sample-point-data = <800>;
};
```

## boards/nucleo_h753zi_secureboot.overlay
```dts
/*
 * =============================================================================
 * Xaloqi Zephyr-Reference-ECU
 * boards/nucleo_h753zi_secureboot.overlay
 *
 * Self-contained overlay for the secure-boot build — everything
 * boards/nucleo_h753zi.overlay has (FDCAN1, IWDG, RNG, USART3), plus the
 * MCUboot-aware flash partition table, adapted verbatim from Xaloqi EDS's
 * own confirmed examples/safeboot_ecu/boards/nucleo_h753zi/
 * nucleo_h753zi.overlay. -DDTC_OVERLAY_FILE replaces Zephyr's default
 * overlay list rather than adding to it, so this file has to be complete
 * on its own rather than layered on top of the CAN-only overlay.
 *
 * Scoped per the proposal's ⬥7 / README.md "Phase 4": wires up exactly
 * what EDS ships today (MCUboot swap, image-policy gate, fail-closed
 * production guard). Firmware authenticity / anti-rollback
 * (EDS#319) is open upstream and explicitly excluded — see README.md.
 * =============================================================================
 */

#include <zephyr/dt-bindings/pinctrl/stm32-pinctrl.h>

&pinctrl {
	fdcan1_rx_pd0: fdcan1_rx_pd0 {
		pinmux = <STM32_PINMUX('D', 0, AF9)>;
	};
	fdcan1_tx_pd1: fdcan1_tx_pd1 {
		pinmux = <STM32_PINMUX('D', 1, AF9)>;
		slew-rate = "very-high-speed";
	};
};

&fdcan1 {
	status = "okay";
	pinctrl-0 = <&fdcan1_rx_pd0 &fdcan1_tx_pd1>;
	pinctrl-names = "default";
	bitrate      = <500000>;
	sample-point = <875>;
};

/ {
	aliases {
		can0 = &fdcan1;
		watchdog0 = &iwdg;
	};
};

&iwdg {
	status = "okay";
};

&rng {
	status = "okay";
};

/ {
	chosen {
		zephyr,entropy = &rng;
	};
};

&usart3 {
	status = "okay";
	current-speed = <115200>;
	pinctrl-0 = <&usart3_tx_pd8 &usart3_rx_pd9>;
	pinctrl-names = "default";
};

/* ── Flash partition table — MCUboot + app slots + NVS ─────────────────────
 *
 * STM32H753ZI: 2 MB flash, base 0x08000000, 128 KB sectors (dual-bank).
 *
 *   Offset     Size    Label        Purpose
 *   ─────────  ──────  ───────────  ─────────────────────────────────────
 *   0x000000   256 KB  mcuboot      MCUboot itself (built separately)
 *   0x040000   768 KB  image-0      Primary application slot
 *   0x100000   768 KB  image-1      Secondary / OTA staging slot
 *   0x1C0000   256 KB  diag_nvs     EDS's NVS store (2x128KB, WL minimum)
 *
 * image-0 and image-1 MUST stay equal size (MCUboot swap requirement);
 * every boundary lands on a 128 KB sector edge (a partial-sector erase
 * would corrupt its neighbour). See EDS's safeboot_ecu/README.md "Flash
 * layout" for the full reasoning — reused verbatim here, not re-derived.
 * ─────────────────────────────────────────────────────────────────────── */
&flash0 {
	/delete-node/ partitions;

	partitions {
		compatible = "fixed-partitions";
		#address-cells = <1>;
		#size-cells = <1>;

		boot_partition: partition@0 {
			label = "mcuboot";
			reg = <0x00000000 0x00040000>;
		};

		slot0_partition: eds_app_slot: partition@40000 {
			label = "image-0";
			reg = <0x00040000 0x000C0000>;
		};

		eds_ota_slot: image_1: slot1_partition: partition@100000 {
			label = "image-1";
			reg = <0x00100000 0x000C0000>;
		};

		eds_nvs_slot: partition@1c0000 {
			label = "diag_nvs";
			reg = <0x001C0000 0x00040000>;
		};
	};
};
```

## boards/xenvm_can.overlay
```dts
/*
 * Xaloqi Zephyr-Reference-ECU — boards/xenvm_can.overlay
 *
 * The CAN variant of xenvm_doip.overlay: the two virtio-mmio slots libxl
 * allocates on Arm for the virtio= entries xenvm/harness/domd-test-can.sh adds
 * to domz.cfg, in that order:
 *   slot 0  0x02000000, SPI 33 (GIC_SPI 1)  virtio-can (can0), device 36
 *   slot 1  0x02000200, SPI 34 (GIC_SPI 2)  virtio-rng (zephyr,entropy)
 * Zephyr's xenvm uses a static devicetree, so the nodes libxl writes into the
 * guest DTB are ignored and are mirrored here. Change one, change both.
 *
 * virtio,device24 is served by the Xaloqi/zephyr-virtio-can module (xenvm/west.yml).
 * Plus the same RAM-backed simulated flash as xenvm_doip.overlay.
 *
 * SPDX-License-Identifier: Apache-2.0
 */
#include <zephyr/dt-bindings/interrupt-controller/arm-gic.h>

/ {
	aliases {
		can0 = &virtio_can;
	};

	chosen {
		zephyr,canbus = &virtio_can;
		zephyr,entropy = &virtio_rng;
	};

	virtio_mmio0: virtio_mmio@2000000 {
		compatible = "virtio,mmio";
		reg = <0x0 0x02000000 0x0 0x200>;
		interrupts = <GIC_SPI 1 IRQ_TYPE_LEVEL IRQ_DEFAULT_PRIORITY>;
		interrupt-parent = <&gic>;
		status = "okay";

		virtio_can: virtio-can {
			compatible = "virtio,device24";
			status = "okay";
		};
	};

	virtio_mmio1: virtio_mmio@2000200 {
		compatible = "virtio,mmio";
		reg = <0x0 0x02000200 0x0 0x200>;
		interrupts = <GIC_SPI 2 IRQ_TYPE_LEVEL IRQ_DEFAULT_PRIORITY>;
		interrupt-parent = <&gic>;
		status = "okay";

		virtio_rng: virtio-rng {
			compatible = "virtio,device4";
			status = "okay";
		};
	};

	sim_flash: sim_flash {
		compatible = "zephyr,sim-flash";
		#address-cells = <1>;
		#size-cells = <1>;
		erase-value = <0xff>;

		flash_sim0: flash_sim@0 {
			compatible = "soc-nv-flash";
			reg = <0x00000000 DT_SIZE_K(64)>;
			erase-block-size = <4096>;
			write-block-size = <4>;

			partitions {
				compatible = "fixed-partitions";
				#address-cells = <1>;
				#size-cells = <1>;

				eds_nvs_slot: partition@0 {
					label = "diag_nvs";
					reg = <0x00000000 DT_SIZE_K(32)>;
				};
			};
		};
	};
};
```

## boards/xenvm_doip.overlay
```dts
/*
 * Xaloqi Zephyr-Reference-ECU — boards/xenvm_doip.overlay
 *
 * The two virtio-mmio slots libxl allocates on Arm for the first two virtio=
 * entries of xenvm/harness/domz.cfg, in that order:
 *   slot 0  0x02000000, SPI 33 (GIC_SPI 1)  virtio-net
 *   slot 1  0x02000200, SPI 34 (GIC_SPI 2)  virtio-rng (zephyr,entropy)
 * Zephyr's xenvm uses a static devicetree, so the nodes libxl writes into the
 * guest DTB are ignored and are mirrored here. Change one, change both.
 *
 * Plus a RAM-backed simulated flash holding the eds_nvs_slot partition that
 * src/main_doip.c's NVM store mounts (xenvm has no flash device).
 *
 * SPDX-License-Identifier: Apache-2.0
 */
#include <zephyr/dt-bindings/interrupt-controller/arm-gic.h>

/ {
	chosen {
		zephyr,entropy = &virtio_rng;
	};

	virtio_mmio0: virtio_mmio@2000000 {
		compatible = "virtio,mmio";
		reg = <0x0 0x02000000 0x0 0x200>;
		interrupts = <GIC_SPI 1 IRQ_TYPE_LEVEL IRQ_DEFAULT_PRIORITY>;
		interrupt-parent = <&gic>;
		status = "okay";

		virtio_net: virtio-net {
			compatible = "virtio,net";
			status = "okay";
			local-mac-address = [00 16 3e 5a 00 01];
		};
	};

	virtio_mmio1: virtio_mmio@2000200 {
		compatible = "virtio,mmio";
		reg = <0x0 0x02000200 0x0 0x200>;
		interrupts = <GIC_SPI 2 IRQ_TYPE_LEVEL IRQ_DEFAULT_PRIORITY>;
		interrupt-parent = <&gic>;
		status = "okay";

		virtio_rng: virtio-rng {
			compatible = "virtio,device4";
			status = "okay";
		};
	};

	sim_flash: sim_flash {
		compatible = "zephyr,sim-flash";
		#address-cells = <1>;
		#size-cells = <1>;
		erase-value = <0xff>;

		flash_sim0: flash_sim@0 {
			compatible = "soc-nv-flash";
			reg = <0x00000000 DT_SIZE_K(64)>;
			erase-block-size = <4096>;
			write-block-size = <4>;

			partitions {
				compatible = "fixed-partitions";
				#address-cells = <1>;
				#size-cells = <1>;

				eds_nvs_slot: partition@0 {
					label = "diag_nvs";
					reg = <0x00000000 DT_SIZE_K(32)>;
				};
			};
		};
	};
};
```

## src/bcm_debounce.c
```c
// SPDX-License-Identifier: Apache-2.0
// Copyright (c) 2026 Xaloqi
/*
 * =============================================================================
 * Xaloqi Zephyr-Reference-ECU
 * FILE: src/bcm_debounce.c
 *
 * PURPOSE: See bcm_debounce.h. Deliberately dependency-free so it can be
 *          unit-tested with plain gcc — see tests/test_bcm_debounce.c.
 * =============================================================================
 */

#include "bcm_debounce.h"

void bcm_debounce_init(bcm_debounce_t *d)
{
    d->set_ticks  = 0U;
    d->heal_ticks = 0U;
    d->active     = false;
}

bool bcm_debounce_update(bcm_debounce_t *d, bool condition_held, uint8_t threshold_ticks)
{
    uint8_t threshold = (threshold_ticks == 0U) ? (uint8_t)1U : threshold_ticks;

    if (condition_held) {
        d->heal_ticks = 0U;
        if (d->set_ticks < threshold) {
            d->set_ticks++;
        }
        if ((!d->active) && (d->set_ticks >= threshold)) {
            d->active = true;
        }
    } else {
        d->set_ticks = 0U;
        if (d->heal_ticks < threshold) {
            d->heal_ticks++;
        }
        if (d->active && (d->heal_ticks >= threshold)) {
            d->active = false;
        }
    }

    return d->active;
}
```

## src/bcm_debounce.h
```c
// SPDX-License-Identifier: Apache-2.0
// Copyright (c) 2026 Xaloqi
/*
 * =============================================================================
 * Xaloqi Zephyr-Reference-ECU
 * FILE: src/bcm_debounce.h
 *
 * PURPOSE: The debounce logic behind both DTC monitors in src/bcm_state.c,
 *          pulled out on purpose: this file has NO Zephyr or EDS dependency
 *          at all, so it is testable with plain gcc — see tests/. Everything
 *          else in src/ needs the full Zephyr+EDS build to even compile.
 * =============================================================================
 */

#ifndef BCM_DEBOUNCE_H
#define BCM_DEBOUNCE_H

#include <stdbool.h>
#include <stdint.h>

#ifdef __cplusplus
extern "C" {
#endif

typedef struct {
    uint8_t set_ticks;    /* consecutive ticks the condition has held */
    uint8_t heal_ticks;   /* consecutive ticks the condition has NOT held */
    bool    active;       /* current debounced state */
} bcm_debounce_t;

/** Reset to the inactive state. */
void bcm_debounce_init(bcm_debounce_t *d);

/**
 * @brief Advance the debounce state machine by one monitor tick.
 *
 * @param d               Debounce state to update.
 * @param condition_held  Whether the raw (un-debounced) fault condition is
 *                         present on this tick.
 * @param threshold_ticks  Consecutive ticks required to flip state in
 *                         either direction. 0 is treated as 1 (an edge on
 *                         the very first tick).
 * @return The debounced `active` state after this tick (same value as
 *         `d->active` on return — returned directly so a caller can read
 *         it without a second field access).
 */
bool bcm_debounce_update(bcm_debounce_t *d, bool condition_held, uint8_t threshold_ticks);

#ifdef __cplusplus
}
#endif

#endif /* BCM_DEBOUNCE_H */
```

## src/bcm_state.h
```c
// SPDX-License-Identifier: Apache-2.0
// Copyright (c) 2026 Xaloqi
/*
 * =============================================================================
 * Xaloqi Zephyr-Reference-ECU
 * FILE: src/bcm_state.h
 *
 * PURPOSE: Application logic for ReferenceBCM — a Body Control Module
 *          reference: door-lock state, a window-position monitor, two DTC
 *          triggers, and the C bodies behind the two RoutineControl
 *          actuations (RID 0x0420 DoorLockAll, RID 0x0421 WindowCalibrate).
 *
 *          This is the part a forker is expected to replace. Diagnostics
 *          (EDS, wired in src/main.c) is the part they are not.
 *
 * THREADING: bcm_state_monitor_tick() is called from diag_task_entry()'s own
 *          loop in src/main.c — the same thread that dispatches UDS requests
 *          (including the 0x2E writes to the two body-state DIDs). Matches
 *          EDS's own examples/vehicle_state_ecu precedent: the generated DID
 *          backing stores have no locking of their own, so a second thread
 *          reading them would race the UDS dispatch thread's writes.
 * =============================================================================
 */

#ifndef BCM_STATE_H
#define BCM_STATE_H

#include "uds_types.h"

#ifdef __cplusplus
extern "C" {
#endif

/** One-time init. Call once from main() before the diag task starts. */
void bcm_state_init(void);

/**
 * @brief Monitor tick. Call once every ~100 ms from diag_task_entry()'s loop.
 *
 * Reads the two body-state DIDs back through their generated accessors,
 * runs the door-ajar and window-stall DTC monitors, and steps any routine
 * in progress (WindowCalibrate's asynchronous walk).
 */
void bcm_state_monitor_tick(void);

/* --------------------------------------------------------------------------
 * RoutineControl bodies — called from generated/routine_handlers.c's four
 * stub bodies (the one hand-edited "generated/ delta" this repo makes; see
 * CMakeLists.txt and the banner at the top of that file).
 * -------------------------------------------------------------------------- */

/** RID 0x0420 startRoutine — lock all doors, arm the door-ajar monitor. */
uds_status_t bcm_state_doorlock_start(
    uint8_t *result_buf, uint8_t result_buf_len, uint8_t *result_len);

/** RID 0x0420 requestRoutineResults — [lock_state, door_status_bitmask]. */
uds_status_t bcm_state_doorlock_results(
    uint8_t *result_buf, uint8_t result_buf_len, uint8_t *result_len);

/** RID 0x0421 startRoutine — begin the asynchronous window travel-learn walk. */
uds_status_t bcm_state_windowcal_start(
    uint8_t *result_buf, uint8_t result_buf_len, uint8_t *result_len);

/** RID 0x0421 requestRoutineResults — poll the calibration walk's verdict. */
uds_status_t bcm_state_windowcal_results(
    uint8_t *result_buf, uint8_t result_buf_len, uint8_t *result_len);

#ifdef __cplusplus
}
#endif

#endif /* BCM_STATE_H */
```
